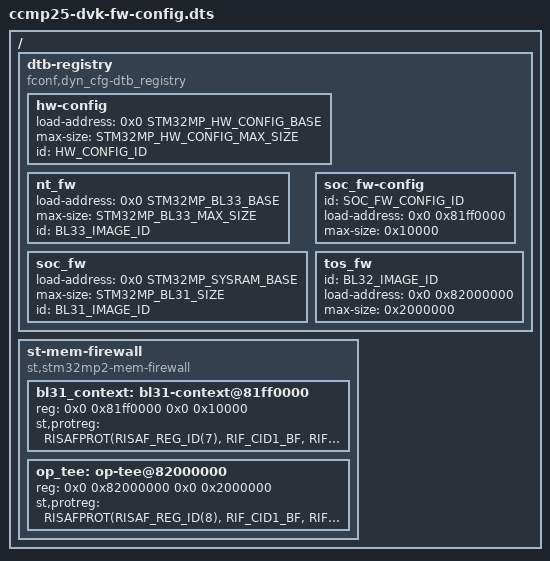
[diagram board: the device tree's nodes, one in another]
// SPDX-License-Identifier: (GPL-2.0+ OR BSD-3-Clause)
/*
 * Copyright (c) 2020-2023, STMicroelectronics - All Rights Reserved
 * Copyright (C) 2024, Digi International Inc - All Rights Reserved
 */

#include <common/tbbr/tbbr_img_def.h>

#include <platform_def.h>

/dts-v1/;

/ {
	dtb-registry {
		compatible = "fconf,dyn_cfg-dtb_registry";

		hw-config {
			load-address = <0x0 STM32MP_HW_CONFIG_BASE>;
			max-size = <STM32MP_HW_CONFIG_MAX_SIZE>;
			id = <HW_CONFIG_ID>;
		};

		nt_fw {
			load-address = <0x0 STM32MP_BL33_BASE>;
			max-size = <STM32MP_BL33_MAX_SIZE>;
			id = <BL33_IMAGE_ID>;
		};

		soc_fw {
			load-address = <0x0 STM32MP_SYSRAM_BASE>;
			max-size = <STM32MP_BL31_SIZE>;
			id = <BL31_IMAGE_ID>;
		};

		soc_fw-config {
			id = <SOC_FW_CONFIG_ID>;
			load-address = <0x0 0x81ff0000>;
			max-size = <0x10000>;
		};

		tos_fw {
			id = <BL32_IMAGE_ID>;
			load-address = <0x0 0x82000000>;
			max-size = <0x2000000>;
		};
	};

	st-mem-firewall {
		compatible = "st,stm32mp2-mem-firewall";
		#address-cells = <2>;
		#size-cells = <2>;

		bl31_context: bl31-context@81ff0000 {
			reg = <0x0 0x81ff0000 0x0 0x10000>;
			st,protreg = <RISAFPROT(RISAF_REG_ID(7), RIF_CID1_BF, RIF_CID1_BF, RIF_CID1_BF, RIF_SEC, RIF_ENC_EN, RIF_BREN_EN)>;
		};
		op_tee: op-tee@82000000 {
			reg = <0x0 0x82000000 0x0 0x2000000>;
			st,protreg = <RISAFPROT(RISAF_REG_ID(8), RIF_CID1_BF, RIF_CID1_BF, 0, RIF_SEC, RIF_ENC_EN, RIF_BREN_EN)>;
		};
	};
};
